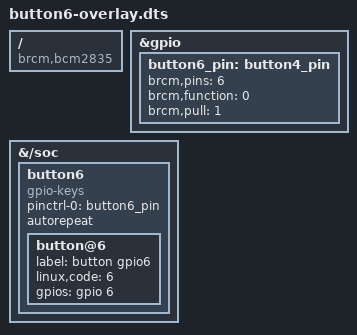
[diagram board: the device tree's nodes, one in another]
/dts-v1/;
/plugin/;

/ {
    compatible = "brcm,bcm2835", "brcm,bcm2708", "brcm,bcm2709";

    fragment@0 {
        target = <&gpio>;
        __overlay__ {
            button6_pin: button4_pin {
                brcm,pins = <6>;     /* gpio6 */
                brcm,function = <0>; /* input */
                brcm,pull = <1>;     /* pull-down */
            };
        };
    };

    fragment@1 {
    target-path = "/soc";
        __overlay__ {
            button6: button6 {
                compatible = "gpio-keys";
                #address-cells = <1>;
                #size-cells = <0>;
                pinctrl-names = "default";
                pinctrl-0 = <&button6_pin>;
                status = "okay";
                autorepeat;

                button@6 {
                    label = "button gpio6";
                    linux,code = <6>;
                    gpios = <&gpio 6 0>;
                };
            };
        };
    };
};

